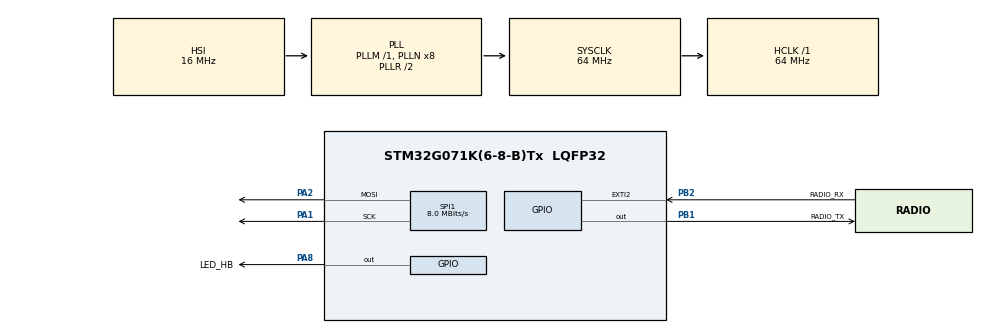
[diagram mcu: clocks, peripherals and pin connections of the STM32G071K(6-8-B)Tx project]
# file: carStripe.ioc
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Dma.Request0=SPI1_TX
Dma.SPI1_TX.0.Direction=DMA_MEMORY_TO_PERIPH
Dma.SPI1_TX.0.EventEnable=DISABLE
Dma.SPI1_TX.0.Instance=DMA1_Channel1
Dma.SPI1_TX.0.MemDataAlignment=DMA_MDATAALIGN_BYTE
Dma.SPI1_TX.0.MemInc=DMA_MINC_ENABLE
Dma.SPI1_TX.0.Mode=DMA_NORMAL
Dma.SPI1_TX.0.PeriphDataAlignment=DMA_PDATAALIGN_BYTE
Dma.SPI1_TX.0.PeriphInc=DMA_PINC_DISABLE
Dma.SPI1_TX.0.Polarity=HAL_DMAMUX_REQ_GEN_RISING
Dma.SPI1_TX.0.Priority=DMA_PRIORITY_HIGH
Dma.SPI1_TX.0.RequestNumber=1
Dma.SPI1_TX.0.SignalID=NONE
Dma.SPI1_TX.0.SyncEnable=DISABLE
Dma.SPI1_TX.0.SyncPolarity=HAL_DMAMUX_SYNC_NO_EVENT
Dma.SPI1_TX.0.SyncRequestNumber=1
Dma.SPI1_TX.0.SyncSignalID=NONE
Mcu.Family=STM32G0
Mcu.Name=STM32G071K(6-8-B)Tx
Mcu.Package=LQFP32
NVIC.DMA1_Channel1_IRQn=true\:0\:0\:false\:false\:true\:false\:true\:true
NVIC.EXTI2_3_IRQn=true\:0\:0\:false\:false\:true\:true\:true\:true
PA1.Mode=TX_Only_Simplex_Unidirect_Master
PA1.Signal=SPI1_SCK
PA13.Mode=Serial_Wire
PA13.Signal=SYS_SWDIO
PA14-BOOT0.Mode=Serial_Wire
PA14-BOOT0.Signal=SYS_SWCLK
PA2.Mode=TX_Only_Simplex_Unidirect_Master
PA2.Signal=SPI1_MOSI
PA8.GPIO_Label=LED_HB
PA8.Signal=GPIO_Output
PB1.GPIO_Label=RADIO_TX
PB1.Signal=GPIO_Output
PB2.GPIO_Label=RADIO_RX
PB2.GPIO_ModeDefaultEXTI=GPIO_MODE_IT_RISING_FALLING
PB2.GPIO_PuPd=GPIO_PULLUP
PB2.Signal=GPXTI2
ProjectManager.HeapSize=0x200
ProjectManager.StackSize=0x400
ProjectManager.TargetToolchain=STM32CubeIDE
RCC.ADCFreq_Value=64000000
RCC.AHBFreq_Value=64000000
RCC.CortexFreq_Value=64000000
RCC.EXTERNAL_CLOCK_VALUE=48000
RCC.HCLKFreq_Value=64000000
RCC.HSE_VALUE=8000000
RCC.HSI_VALUE=16000000
RCC.LSE_VALUE=32768
RCC.SYSCLKFreq_VALUE=64000000
RCC.SYSCLKSource=RCC_SYSCLKSOURCE_PLLCLK
RCC.VCOOutputFreq_Value=128000000
SPI1.BaudRatePrescaler=SPI_BAUDRATEPRESCALER_8
SPI1.CalculateBaudRate=8.0 MBits/s
SPI1.DataSize=SPI_DATASIZE_8BIT
SPI1.Direction=SPI_DIRECTION_2LINES
SPI1.Mode=SPI_MODE_MASTER
SPI1.VirtualType=VM_MASTER
TIM16.Prescaler=511
TIM17.Prescaler=511
VP_SYS_VS_DBSignals.Mode=DisableDeadBatterySignals
VP_TIM16_VS_ClockSourceINT.Mode=Enable_Timer
VP_TIM17_VS_ClockSourceINT.Mode=Enable_Timer
board=custom

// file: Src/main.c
/* USER CODE BEGIN Header */
/**
 ******************************************************************************
 * @file           : main.c
 * @brief          : Main program body
 ******************************************************************************
 * @attention
 *
 * Copyright (c) 2024 STMicroelectronics.
 * All rights reserved.
 *
 * This software is licensed under terms that can be found in the LICENSE file
 * in the root directory of this software component.
 * If no LICENSE file comes with this software, it is provided AS-IS.
 *
 ******************************************************************************
 */
/* USER CODE END Header */
#include "main.h"
#include "dma.h"
#include "spi.h"
#include "tim.h"
#include "gpio.h"

/* USER CODE BEGIN Includes */
#include "carstripe.h"
/* USER CODE END Includes */

void SystemClock_Config(void);

int main(void)
{

  /* MCU Configuration--------------------------------------------------------*/

  /* Reset of all peripherals, Initializes the Flash interface and the Systick. */
  HAL_Init();

  /* Configure the system clock */
  SystemClock_Config();

  /* Initialize all configured peripherals */
  MX_GPIO_Init();
  MX_DMA_Init();
  MX_SPI1_Init();
  MX_TIM16_Init();
  MX_TIM17_Init();
  /* USER CODE BEGIN 2 */
	carStripe();
  /* USER CODE END 2 */

  /* Infinite loop */
	while (1) {

	}
}

void SystemClock_Config(void)
{
  RCC_OscInitTypeDef RCC_OscInitStruct = {0};
  RCC_ClkInitTypeDef RCC_ClkInitStruct = {0};

  /** Configure the main internal regulator output voltage
  */
  HAL_PWREx_ControlVoltageScaling(PWR_REGULATOR_VOLTAGE_SCALE1);

  /** Initializes the RCC Oscillators according to the specified parameters
  * in the RCC_OscInitTypeDef structure.
  */
  RCC_OscInitStruct.OscillatorType = RCC_OSCILLATORTYPE_HSI;
  RCC_OscInitStruct.HSIState = RCC_HSI_ON;
  RCC_OscInitStruct.HSIDiv = RCC_HSI_DIV1;
  RCC_OscInitStruct.HSICalibrationValue = RCC_HSICALIBRATION_DEFAULT;
  RCC_OscInitStruct.PLL.PLLState = RCC_PLL_ON;
  RCC_OscInitStruct.PLL.PLLSource = RCC_PLLSOURCE_HSI;
  RCC_OscInitStruct.PLL.PLLM = RCC_PLLM_DIV1;
  RCC_OscInitStruct.PLL.PLLN = 8;
  RCC_OscInitStruct.PLL.PLLP = RCC_PLLP_DIV2;
  RCC_OscInitStruct.PLL.PLLQ = RCC_PLLQ_DIV2;
  RCC_OscInitStruct.PLL.PLLR = RCC_PLLR_DIV2;
  if (HAL_RCC_OscConfig(&RCC_OscInitStruct) != HAL_OK)
  {
    Error_Handler();
  }

  /** Initializes the CPU, AHB and APB buses clocks
  */
  RCC_ClkInitStruct.ClockType = RCC_CLOCKTYPE_HCLK|RCC_CLOCKTYPE_SYSCLK
                              |RCC_CLOCKTYPE_PCLK1;
  RCC_ClkInitStruct.SYSCLKSource = RCC_SYSCLKSOURCE_PLLCLK;
  RCC_ClkInitStruct.AHBCLKDivider = RCC_SYSCLK_DIV1;
  RCC_ClkInitStruct.APB1CLKDivider = RCC_HCLK_DIV1;

  if (HAL_RCC_ClockConfig(&RCC_ClkInitStruct, FLASH_LATENCY_2) != HAL_OK)
  {
    Error_Handler();
  }
}

void Error_Handler(void)
{
	__disable_irq();
	while (1) {
	}
}
